AUTOSAR XML (schema 00050)
package /ComponentTypes
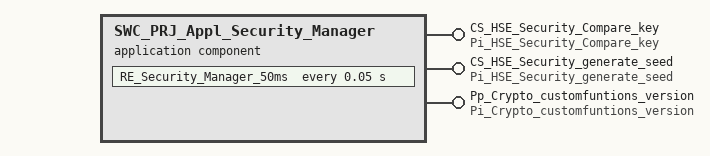
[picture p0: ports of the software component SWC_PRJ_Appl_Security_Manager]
  application sw component type SWC_PRJ_Appl_Security_Manager
    provide port CS_HSE_Security_Compare_key: server-com-spec{operation=Operation, queue-length=1}, provided-interface=Pi_HSE_Security_Compare_key
    provide port CS_HSE_Security_generate_seed: server-com-spec{operation=Operation, queue-length=1}, provided-interface=Pi_HSE_Security_generate_seed
    provide port Pp_Crypto_customfuntions_version: nonqueued-sender-com-spec{data-element=De_Crypto_CustomFunctions_Version, init-value=fields=[containerVersion:0, mwVersion:0, sBoot:0]}, provided-interface=Pi_Crypto_customfuntions_version
    behavior SWC_PRJ_Appl_Security_Manager_InternalBehavior: handle-termination-and-restart=NO-SUPPORT
      operation invoked event OIT_CS_HSE_Security_Compare_key_Operation_CS_HSE_Security_Compare_key_Operation: start-on-event=CS_HSE_Security_Compare_key_Operation, operation=CS_HSE_Security_Compare_key.Operation
      operation invoked event OIT_CS_HSE_Security_generate_seed_Operation_CS_HSE_Security_generate_seed_Operation: start-on-event=CS_HSE_Security_generate_seed_Operation, operation=CS_HSE_Security_generate_seed.Operation
      timing event TMT_RE_Security_Manager_50ms: start-on-event=RE_Security_Manager_50ms, period=0.05
      init event RE_Security_Manager_InitEvent: start-on-event=RE_Security_Manager_Init
      4 x runnable:
        CS_HSE_Security_Compare_key_Operation
        CS_HSE_Security_generate_seed_Operation
        RE_Security_Manager_50ms
          data-send-points:
            access SEND_Pp_Crypto_customfuntions_version_De_Crypto_CustomFunctions_Version: accessed-variable=Pp_Crypto_customfuntions_version.De_Crypto_CustomFunctions_Version
        RE_Security_Manager_Init
  swc implementation SWC_PRJ_Appl_Security_Manager_Implementation: behavior=SWC_PRJ_Appl_Security_Manager_InternalBehavior
